AUTOSAR XML (schema 4-2-2)
package /Components
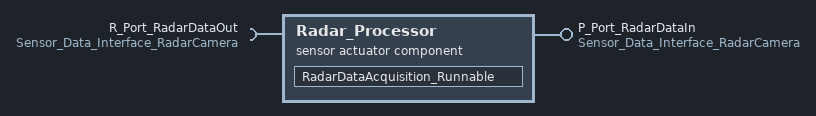
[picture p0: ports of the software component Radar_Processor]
  sensor actuator sw component type Radar_Processor
    provide port P_Port_RadarDataIn: provided-interface=Sensor_Data_Interface_RadarCamera
    require port R_Port_RadarDataOut: required-interface=Sensor_Data_Interface_RadarCamera, symbol=RadarDataOutSymbol
    behavior RadarDataAcquisition_BHV
      data received event RadarDataReady: start-on-event=RadarDataAcquisition_Runnable, event-source=RadarData
      data send completed event RadarDataSent: start-on-event=RadarDataAcquisition_Runnable, event-source=RadarData
      runnable RadarDataAcquisition_Runnable: notes=RadarDataAcquisition_Runnable handles input RadarData and outputs RadarData via RadarDataOut
        data-receive-point-by-arguments:
          access RadarDataInput: accessed-variable=P_Port_RadarDataIn.RadarData
        data-send-points:
          access RadarDataOutput: accessed-variable=R_Port_RadarDataOut.RadarData
